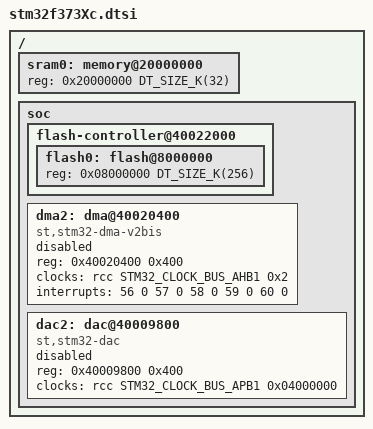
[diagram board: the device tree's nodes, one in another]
/*
 * Copyright (c) 2018 Linaro Limited
 *
 * SPDX-License-Identifier: Apache-2.0
 */

#include <mem.h>
#include <st/f3/stm32f373.dtsi>

/ {
	sram0: memory@20000000 {
		reg = <0x20000000 DT_SIZE_K(32)>;
	};

	soc {
		flash-controller@40022000 {
			flash0: flash@8000000 {
				reg = <0x08000000 DT_SIZE_K(256)>;
			};
		};

		dma2: dma@40020400 {
			compatible = "st,stm32-dma-v2bis";
			reg = <0x40020400 0x400>;
			clocks = <&rcc STM32_CLOCK_BUS_AHB1 0x2>;
			interrupts = <56 0 57 0 58 0 59 0 60 0>;
			status = "disabled";
		};

		dac2: dac@40009800 {
			compatible = "st,stm32-dac";
			reg = <0x40009800 0x400>;
			clocks = <&rcc STM32_CLOCK_BUS_APB1 0x04000000>;
			status = "disabled";
			#io-channel-cells = <1>;
		};
	};
};
